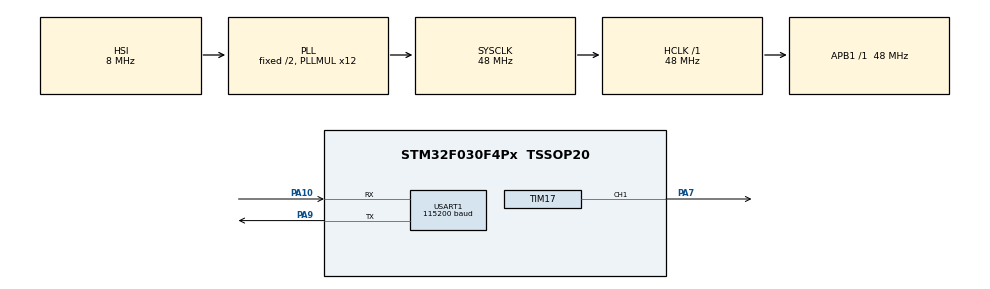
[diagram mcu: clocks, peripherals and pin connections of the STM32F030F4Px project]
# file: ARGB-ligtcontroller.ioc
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Dma.Request0=TIM17_CH1/UP
Dma.Request1=USART1_RX
Dma.TIM17_CH1/UP.0.Direction=DMA_MEMORY_TO_PERIPH
Dma.TIM17_CH1/UP.0.Instance=DMA1_Channel1
Dma.TIM17_CH1/UP.0.MemDataAlignment=DMA_MDATAALIGN_HALFWORD
Dma.TIM17_CH1/UP.0.MemInc=DMA_MINC_ENABLE
Dma.TIM17_CH1/UP.0.Mode=DMA_NORMAL
Dma.TIM17_CH1/UP.0.PeriphDataAlignment=DMA_PDATAALIGN_HALFWORD
Dma.TIM17_CH1/UP.0.PeriphInc=DMA_PINC_DISABLE
Dma.TIM17_CH1/UP.0.Priority=DMA_PRIORITY_VERY_HIGH
Dma.USART1_RX.1.Direction=DMA_PERIPH_TO_MEMORY
Dma.USART1_RX.1.Instance=DMA1_Channel5
Dma.USART1_RX.1.MemDataAlignment=DMA_MDATAALIGN_BYTE
Dma.USART1_RX.1.MemInc=DMA_MINC_ENABLE
Dma.USART1_RX.1.Mode=DMA_NORMAL
Dma.USART1_RX.1.PeriphDataAlignment=DMA_PDATAALIGN_BYTE
Dma.USART1_RX.1.PeriphInc=DMA_PINC_DISABLE
Dma.USART1_RX.1.Priority=DMA_PRIORITY_LOW
Mcu.Family=STM32F0
Mcu.Name=STM32F030F4Px
Mcu.Package=TSSOP20
NVIC.DMA1_Channel1_IRQn=true\:0\:0\:false\:false\:true\:true\:true\:true
NVIC.USART1_IRQn=true\:0\:0\:false\:false\:true\:true\:true\:true
PA10.Mode=Asynchronous
PA10.Signal=USART1_RX
PA13.Mode=Serial_Wire
PA13.Signal=SYS_SWDIO
PA14.Mode=Serial_Wire
PA14.Signal=SYS_SWCLK
PA7.GPIO_Speed=GPIO_SPEED_FREQ_HIGH
PA7.Signal=S_TIM17_CH1
PA9.Mode=Asynchronous
PA9.Signal=USART1_TX
PF0-OSC_IN.Mode=HSE-External-Oscillator
PF0-OSC_IN.Signal=RCC_OSC_IN
PF1-OSC_OUT.Mode=HSE-External-Oscillator
PF1-OSC_OUT.Signal=RCC_OSC_OUT
ProjectManager.HeapSize=0x800
ProjectManager.StackSize=0x200
ProjectManager.TargetToolchain=MDK-ARM V5.32
RCC.AHBFreq_Value=48000000
RCC.APB1Freq_Value=48000000
RCC.APB1TimFreq_Value=48000000
RCC.HCLKFreq_Value=48000000
RCC.PLLMUL=RCC_PLL_MUL12
RCC.SYSCLKFreq_VALUE=48000000
RCC.SYSCLKSource=RCC_SYSCLKSOURCE_PLLCLK
SH.S_TIM17_CH1.0=TIM17_CH1,PWM Generation1 CH1
TIM17.Channel=TIM_CHANNEL_1
TIM17.Period=60
USART1.BaudRate=115200
USART1.VirtualMode-Asynchronous=VM_ASYNC
VP_TIM17_VS_ClockSourceINT.Mode=Enable_Timer
board=custom

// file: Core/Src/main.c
/* USER CODE BEGIN Header */
/**
  ******************************************************************************
  * @file           : main.c
  * @brief          : Main program body
  ******************************************************************************
  * @attention
  *
  * Copyright (c) 2024 STMicroelectronics.
  * All rights reserved.
  *
  * This software is licensed under terms that can be found in the LICENSE file
  * in the root directory of this software component.
  * If no LICENSE file comes with this software, it is provided AS-IS.
  *
  ******************************************************************************
  */
/* USER CODE END Header */
#include "main.h"
#include "dma.h"
#include "tim.h"
#include "usart.h"
#include "gpio.h"

/* USER CODE BEGIN Includes */
#include "stdio.h"
#include "ws2812.h"
/* USER CODE END Includes */

/* USER CODE BEGIN PV */
extern uint8_t uart_rx_buf[];
__IO uint8_t CPU_Temp[2];//0:lastval 1:curval
__IO uint8_t info_update_flag;
__IO uint8_t CPU_Used;
/* USER CODE END PV */

void SystemClock_Config(void);

/* USER CODE BEGIN 0 */
int fputc(int ch, FILE *f)
{
  HAL_UART_Transmit(&huart1, (uint8_t *)&ch, 1, HAL_MAX_DELAY);
  return ch;
}
/* USER CODE END 0 */

int main(void)
{

  /* MCU Configuration--------------------------------------------------------*/

  /* Reset of all peripherals, Initializes the Flash interface and the Systick. */
  HAL_Init();

  /* Configure the system clock */
  SystemClock_Config();

  /* Initialize all configured peripherals */
  MX_GPIO_Init();
  MX_DMA_Init();
  MX_USART1_UART_Init();
  MX_TIM17_Init();
  /* USER CODE BEGIN 2 */
  printf("Init done\r\n");
  HAL_UARTEx_ReceiveToIdle_DMA(&huart1,uart_rx_buf,50);
  /* USER CODE END 2 */
  /* Infinite loop */
  /* USER CODE BEGIN WHILE */
	//WS2812_Rainbow(50);
	WS2812_RunningHorse(95,10);
  while (1)
  {
    /* USER CODE END WHILE */

  }
}

void SystemClock_Config(void)
{
  RCC_OscInitTypeDef RCC_OscInitStruct = {0};
  RCC_ClkInitTypeDef RCC_ClkInitStruct = {0};
  RCC_PeriphCLKInitTypeDef PeriphClkInit = {0};

  /** Initializes the RCC Oscillators according to the specified parameters
  * in the RCC_OscInitTypeDef structure.
  */
  RCC_OscInitStruct.OscillatorType = RCC_OSCILLATORTYPE_HSI;
  RCC_OscInitStruct.HSIState = RCC_HSI_ON;
  RCC_OscInitStruct.HSICalibrationValue = RCC_HSICALIBRATION_DEFAULT;
  RCC_OscInitStruct.PLL.PLLState = RCC_PLL_ON;
  RCC_OscInitStruct.PLL.PLLSource = RCC_PLLSOURCE_HSI;
  RCC_OscInitStruct.PLL.PLLMUL = RCC_PLL_MUL12;
  RCC_OscInitStruct.PLL.PREDIV = RCC_PREDIV_DIV1;
  if (HAL_RCC_OscConfig(&RCC_OscInitStruct) != HAL_OK)
  {
    Error_Handler();
  }

  /** Initializes the CPU, AHB and APB buses clocks
  */
  RCC_ClkInitStruct.ClockType = RCC_CLOCKTYPE_HCLK|RCC_CLOCKTYPE_SYSCLK
                              |RCC_CLOCKTYPE_PCLK1;
  RCC_ClkInitStruct.SYSCLKSource = RCC_SYSCLKSOURCE_PLLCLK;
  RCC_ClkInitStruct.AHBCLKDivider = RCC_SYSCLK_DIV1;
  RCC_ClkInitStruct.APB1CLKDivider = RCC_HCLK_DIV1;

  if (HAL_RCC_ClockConfig(&RCC_ClkInitStruct, FLASH_LATENCY_1) != HAL_OK)
  {
    Error_Handler();
  }
  PeriphClkInit.PeriphClockSelection = RCC_PERIPHCLK_USART1;
  PeriphClkInit.Usart1ClockSelection = RCC_USART1CLKSOURCE_PCLK1;
  if (HAL_RCCEx_PeriphCLKConfig(&PeriphClkInit) != HAL_OK)
  {
    Error_Handler();
  }
}

void Error_Handler(void)
{
  __disable_irq();
  while (1)
  {
  }
}
